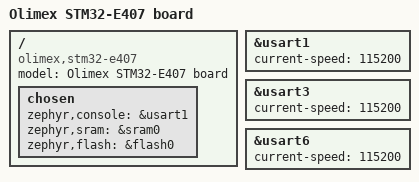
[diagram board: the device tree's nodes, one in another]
/*
 * Copyright (c) 2017, Erwin Rol <erwin@erwinrol.com>
 *
 * SPDX-License-Identifier: Apache-2.0
 */

/dts-v1/;
#include <st/stm32f407.dtsi>

/ {
	model = "Olimex STM32-E407 board";
	compatible = "olimex,stm32-e407", "st,stm32f407";

	chosen {
		zephyr,console = &usart1;
		zephyr,sram = &sram0;
		zephyr,flash = &flash0;
	};
};

&usart1 {
	current-speed = <115200>;
	status = "ok";
};

&usart3 {
	current-speed = <115200>;
	status = "ok";
};

&usart6 {
	current-speed = <115200>;
	status = "ok";
};

